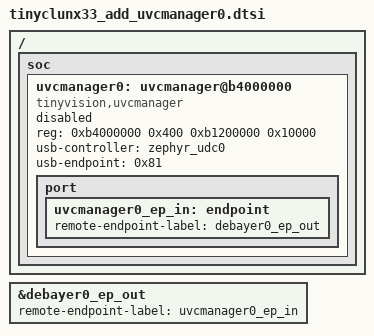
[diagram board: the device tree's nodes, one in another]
/*
 * Copyright (c) 2024-2025 tinyVision.ai Inc.
 *
 * SPDX-License-Identifier: Apache-2.0
 */

/ {
	soc {
		uvcmanager0: uvcmanager@b4000000 {
			compatible = "tinyvision,uvcmanager";
			reg = <0xb4000000 0x400
			       0xb1200000 0x10000>;
			reg-names = "base",
				    "fifo";
			usb-controller = <&zephyr_udc0>;
			usb-endpoint = <0x81>;
			status = "disabled";

			port {
				uvcmanager0_ep_in: endpoint {
					remote-endpoint-label = "debayer0_ep_out";
				};
			};
		};
	};
};

&debayer0_ep_out {
	remote-endpoint-label = "uvcmanager0_ep_in";
};
